# STM32L562 register map
File version: 1.1
Registers are 32-bit, read-write, reset 0x0 unless marked. A register's access mark holds for its fields unless they carry their own. Offsets are from the block's base; [hi:lo] are bit positions; {n}, {i} and the like mark numbered series.

## WWDG — System window watchdog
Base 0x40002C00
Same registers: SEC_WWDG 0x50002C00
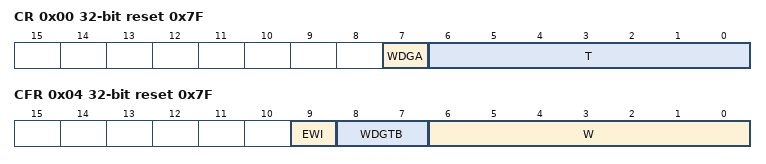
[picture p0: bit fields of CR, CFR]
0x00 CR reset 0x7F — Control register
  [7] WDGA — Activation bit
  [6:0] T — 7-bit counter (MSB to LSB)
0x04 CFR reset 0x7F — Configuration register
  [9] EWI — Early wakeup interrupt
  [8:7] WDGTB — Timer base
  [6:0] W — 7-bit window value
0x08 SR — Status register
  [0] EWIF — Early wakeup interrupt flag

## SYSCFG — System configuration controller
Base 0x40010000
Same registers: SEC_SYSCFG 0x50010000
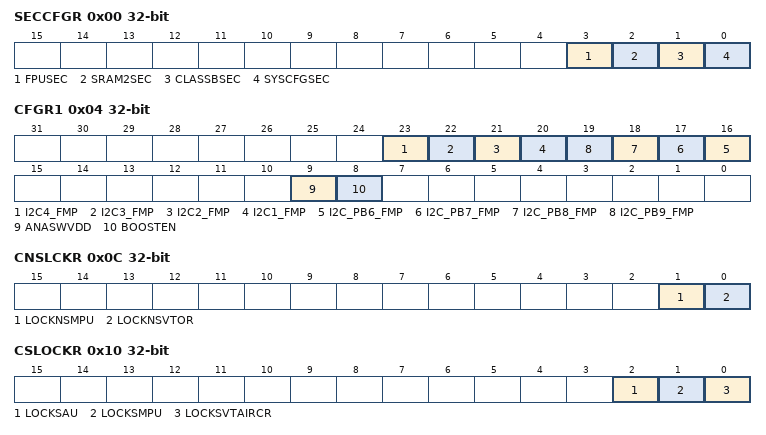
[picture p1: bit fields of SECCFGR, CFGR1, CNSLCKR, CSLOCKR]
0x00 SECCFGR — SYSCFG secure configuration register
  [3] FPUSEC
  [2] SRAM2SEC — SRAM2 security
  [1] CLASSBSEC — ClassB security
  [0] SYSCFGSEC — SYSCFG clock control security
0x04 CFGR1 — configuration register 1
  [23] I2C4_FMP
  [22] I2C3_FMP — I2C3 Fast-mode Plus driving capability activation
  [21] I2C2_FMP — I2C2 Fast-mode Plus driving capability activation
  [20] I2C1_FMP — I2C1 Fast-mode Plus driving capability activation
  [n+10] I2C_PB{n}_FMP (n=6..9) — Fast-mode Plus (Fm+) driving capability activation on PB{n}
  [9] ANASWVDD — GPIO analog switch control voltage selection
  [8] BOOSTEN — I/O analog switch voltage booster enable
0x08 FPUIMR reset 0x1F — FPU interrupt mask register
  [5:0] FPU_IE — Floating point unit interrupts enable bits
0x0C CNSLCKR — SYSCFG CPU non-secure lock register
  [1] LOCKNSMPU — Non-secure MPU registers lock
  [0] LOCKNSVTOR — VTOR_NS register lock
0x10 CSLOCKR — SYSCFG CPU secure lock register
  [2] LOCKSAU, [1] LOCKSMPU, [0] LOCKSVTAIRCR
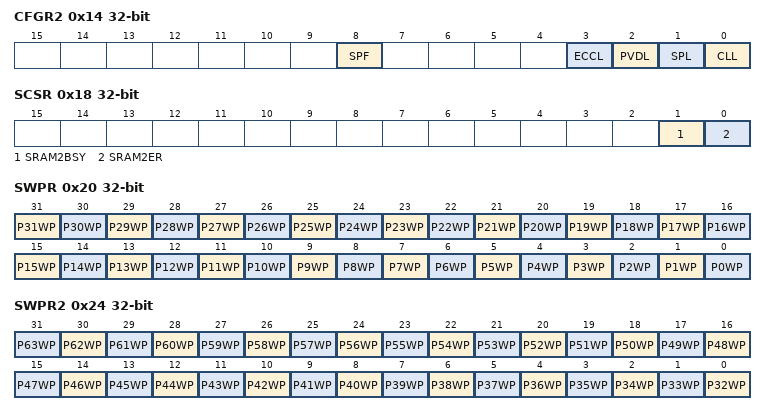
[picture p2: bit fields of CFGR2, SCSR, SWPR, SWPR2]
0x14 CFGR2 access per field
  [8] SPF rw — SRAM2 parity error flag
  [3] ECCL wo — ECC Lock
  [2] PVDL wo — PVD lock enable bit
  [1] SPL wo — SRAM2 parity lock bit
  [0] CLL wo — LOCKUP (hardfault) output enable bit
0x18 SCSR access per field
  [1] SRAM2BSY ro — SRAM2 busy by erase operation
  [0] SRAM2ER rw — SRAM2 Erase
0x1C SKR wo
  [7:0] KEY — SRAM2 write protection key for software erase
0x20 SWPR wo
  [31] P31WP — SRAM2 page 31 write protection
  [n] P{n}WP (n=0..30)
0x24 SWPR2 wo
  [n-32] P{n}WP (n=32..63)
0x2C RSSCMDR
  [7:0] RSSCMD — RSS commands

## DBGMCU — MCU debug component
Base 0xE0044000
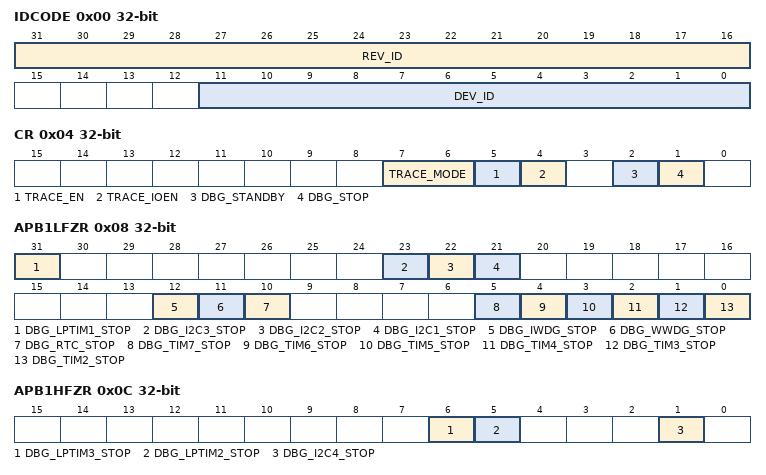
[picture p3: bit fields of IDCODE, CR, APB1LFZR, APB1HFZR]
0x00 IDCODE ro — DBGMCU_IDCODE
  [31:16] REV_ID — Revision identifie
  [11:0] DEV_ID — Device identifier
0x04 CR — Debug MCU configuration register
  [7:6] TRACE_MODE — Trace pin assignment control
  [5] TRACE_EN — trace port and clock enable
  [4] TRACE_IOEN — Trace pin assignment control
  [2] DBG_STANDBY — Debug Standby mode
  [1] DBG_STOP — Debug Stop mode
0x08 APB1LFZR — Debug MCU APB1 freeze register1
  [31] DBG_LPTIM1_STOP — LPTIM1 counter stopped when core is halted
  [23] DBG_I2C3_STOP — I2C3 SMBUS timeout counter stopped when core is halted
  [22] DBG_I2C2_STOP — I2C2 SMBUS timeout counter stopped when core is halted
  [21] DBG_I2C1_STOP — I2C1 SMBUS timeout counter stopped when core is halted
  [12] DBG_IWDG_STOP — Independent watchdog counter stopped when core is halted
  [11] DBG_WWDG_STOP — Window watchdog counter stopped when core is halted
  [10] DBG_RTC_STOP — RTC counter stopped when core is halted
  [5] DBG_TIM7_STOP — TIM7 counter stopped when core is halted
  [4] DBG_TIM6_STOP — TIM6 counter stopped when core is halted
  [3] DBG_TIM5_STOP — TIM5 stop in debug
  [2] DBG_TIM4_STOP — TIM4 stop in debug
  [1] DBG_TIM3_STOP — TIM3 stop in debug
  [0] DBG_TIM2_STOP — TIM2 counter stopped when core is halted
0x0C APB1HFZR — Debug MCU APB1 freeze register 2
  [6] DBG_LPTIM3_STOP — LPTIM3 stop in debug
  [5] DBG_LPTIM2_STOP — LPTIM2 counter stopped when core is halted
  [1] DBG_I2C4_STOP — I2C4 stop in debug
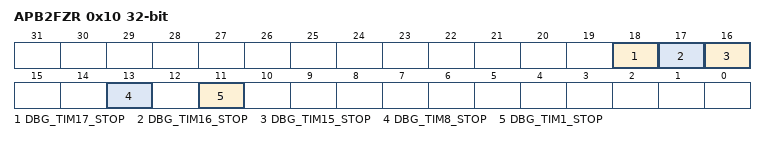
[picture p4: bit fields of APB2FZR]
0x10 APB2FZR — Debug MCU APB2 freeze register
  [18] DBG_TIM17_STOP
  [17] DBG_TIM16_STOP — TIM16 counter stopped when core is halted
  [16] DBG_TIM15_STOP — TIM15 counter stopped when core is halted
  [13] DBG_TIM8_STOP — TIM8 stop in debug
  [11] DBG_TIM1_STOP — TIM1 counter stopped when core is halted
